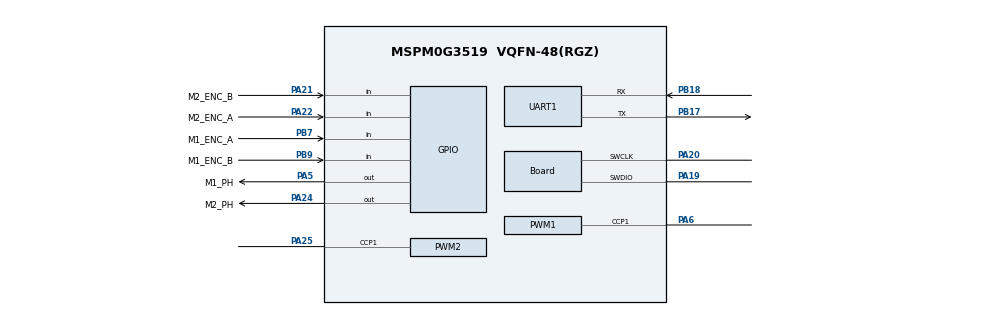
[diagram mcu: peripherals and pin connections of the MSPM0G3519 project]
/**
 * These arguments were used when this file was generated. They will be automatically applied on subsequent loads
 * via the GUI or CLI. Run CLI with '--help' for additional information on how to override these arguments.
 */
//@cliArgs --device "MSPM0G351X" --package "VQFN-48(RGZ)" --part "Default"
//@v2CliArgs --device "MSPM0G3519" --package "VQFN-48(RGZ)"
// @cliArgs --board /ti/boards/LP_MSPM0G3519 --rtos nortos

/**
 * Import the modules used in this configuration.
 */
const SYSCTL = scripting.addModule("/ti/driverlib/SYSCTL");
const GPIO   = scripting.addModule("/ti/driverlib/GPIO", {}, false);
const PWM    = scripting.addModule("/ti/driverlib/PWM", {}, false);
const UART   = scripting.addModule("/ti/driverlib/UART", {}, false);
const GPIO1  = GPIO.addInstance();
const GPIO2  = GPIO.addInstance();
const GPIO3  = GPIO.addInstance();
const PWM1   = PWM.addInstance();
const PWM2   = PWM.addInstance();
const UART1  = UART.addInstance();

/**
 * Write custom configuration values to the imported modules.
 */
SYSCTL.forceDefaultClkConfig = true;
SYSCTL.clockTreeEn           = true;

GPIO1.$name                          = "GPIO_M1_PH";
GPIO1.associatedPins[0].$name        = "M1_PH";
GPIO1.associatedPins[0].direction    = "OUTPUT";
GPIO1.associatedPins[0].initialValue = "CLEARED";
GPIO1.associatedPins[0].assignedPort = "PORTA";
GPIO1.associatedPins[0].assignedPin  = "5";
GPIO1.associatedPins[0].pin.$assign  = "PA5";

GPIO2.$name                          = "GPIO_M2_PH";
GPIO2.associatedPins[0].$name        = "M2_PH";
GPIO2.associatedPins[0].direction    = "OUTPUT";
GPIO2.associatedPins[0].initialValue = "CLEARED";
GPIO2.associatedPins[0].assignedPort = "PORTA";
GPIO2.associatedPins[0].assignedPin  = "24";
GPIO2.associatedPins[0].pin.$assign  = "PA24";

GPIO3.$name                               = "GPIO_ENCODER";
GPIO3.associatedPins.create(4);
GPIO3.associatedPins[0].$name             = "M1_ENC_A";
GPIO3.associatedPins[0].direction         = "INPUT";
GPIO3.associatedPins[0].internalResistor  = "PULL_UP";
GPIO3.associatedPins[0].assignedPort      = "PORTB";
GPIO3.associatedPins[0].assignedPin       = "7";
GPIO3.associatedPins[0].pin.$assign       = "PB7";
GPIO3.associatedPins[1].$name             = "M1_ENC_B";
GPIO3.associatedPins[1].direction         = "INPUT";
GPIO3.associatedPins[1].internalResistor  = "PULL_UP";
GPIO3.associatedPins[1].assignedPort      = "PORTB";
GPIO3.associatedPins[1].assignedPin       = "9";
GPIO3.associatedPins[1].pin.$assign       = "PB9";
GPIO3.associatedPins[2].$name             = "M2_ENC_A";
GPIO3.associatedPins[2].direction         = "INPUT";
GPIO3.associatedPins[2].internalResistor  = "PULL_UP";
GPIO3.associatedPins[2].assignedPort      = "PORTA";
GPIO3.associatedPins[2].assignedPin       = "22";
GPIO3.associatedPins[2].pin.$assign       = "PA22";
GPIO3.associatedPins[3].$name             = "M2_ENC_B";
GPIO3.associatedPins[3].direction         = "INPUT";
GPIO3.associatedPins[3].internalResistor  = "PULL_UP";
GPIO3.associatedPins[3].assignedPort      = "PORTA";
GPIO3.associatedPins[3].assignedPin       = "21";
GPIO3.associatedPins[3].pin.$assign       = "PA21";

PWM1.$name                      = "PWM_M1_EN";
PWM1.ccIndex                    = [1];
PWM1.timerCount                 = 1600;
PWM1.peripheral.$assign         = "TIMG0";
PWM1.peripheral.ccp1Pin.$assign = "PA6";
PWM1.PWM_CHANNEL_1.$name        = "PWM_M1_EN_CHANNEL";
PWM1.PWM_CHANNEL_1.dutyCycle    = 0;

PWM2.$name                      = "PWM_M2_EN";
PWM2.ccIndex                    = [1];
PWM2.timerCount                 = 1600;
PWM2.peripheral.$assign         = "TIMG12";
PWM2.peripheral.ccp1Pin.$assign = "PA25";
PWM2.PWM_CHANNEL_1.$name        = "PWM_M2_EN_CHANNEL";
PWM2.PWM_CHANNEL_1.dutyCycle    = 0;

UART1.$name                    = "UART_CONTROL";
UART1.rxFifoThreshold          = "DL_UART_RX_FIFO_LEVEL_ONE_ENTRY";
UART1.targetBaudRate           = 115200;
UART1.enableFIFO               = true;
UART1.txFifoThreshold          = "DL_UART_TX_FIFO_LEVEL_3_4_EMPTY";
UART1.enableDMARX              = false;
UART1.enableDMATX              = false;
UART1.enabledInterrupts        = ["RX"];
UART1.peripheral.$assign       = "UART4";
UART1.peripheral.rxPin.$assign = "PB18";
UART1.peripheral.txPin.$assign = "PB17";

const Board                       = scripting.addModule("/ti/driverlib/Board", {}, false);
Board.peripheral.$assign          = "DEBUGSS";
Board.peripheral.swclkPin.$assign = "PA20";
Board.peripheral.swdioPin.$assign = "PA19";

const ProjectConfig              = scripting.addModule("/ti/project_config/ProjectConfig", {}, false);
ProjectConfig.migrationCondition = true;
